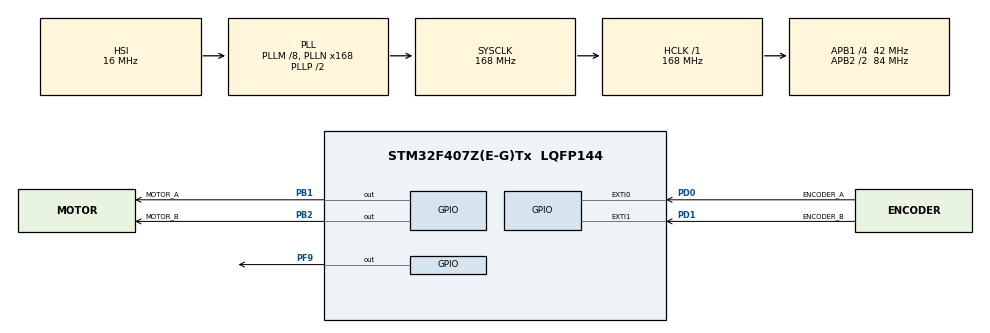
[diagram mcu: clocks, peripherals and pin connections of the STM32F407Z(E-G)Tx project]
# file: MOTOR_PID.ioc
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Mcu.Family=STM32F4
Mcu.Name=STM32F407Z(E-G)Tx
Mcu.Package=LQFP144
NVIC.EXTI0_IRQn=true\:0\:0\:false\:false\:true\:true\:true
NVIC.EXTI1_IRQn=true\:0\:0\:false\:false\:true\:true\:true
NVIC.PriorityGroup=NVIC_PRIORITYGROUP_4
NVIC.TIM2_IRQn=true\:0\:0\:false\:false\:true\:true\:true
NVIC.TIM3_IRQn=true\:0\:0\:false\:false\:true\:true\:true
PA13.Mode=Trace_Asynchronous_SW
PA13.Signal=SYS_JTMS-SWDIO
PA14.Mode=Trace_Asynchronous_SW
PA14.Signal=SYS_JTCK-SWCLK
PB1.GPIO_Label=MOTOR_A
PB1.Signal=GPIO_Output
PB2.GPIO_Label=MOTOR_B
PB2.Signal=GPIO_Output
PB3.Mode=Trace_Asynchronous_SW
PB3.Signal=SYS_JTDO-SWO
PD0.GPIO_Label=ENCODER_A
PD0.GPIO_ModeDefaultEXTI=GPIO_MODE_IT_RISING_FALLING
PD0.Signal=GPXTI0
PD1.GPIO_Label=ENCODER_B
PD1.GPIO_ModeDefaultEXTI=GPIO_MODE_IT_RISING_FALLING
PD1.Signal=GPXTI1
PF9.Signal=GPIO_Output
ProjectManager.HeapSize=0x200
ProjectManager.StackSize=0x400
ProjectManager.TargetToolchain=MDK-ARM V5.32
RCC.48MHZClocksFreq_Value=84000000
RCC.AHBFreq_Value=168000000
RCC.APB1CLKDivider=RCC_HCLK_DIV4
RCC.APB1Freq_Value=42000000
RCC.APB1TimFreq_Value=84000000
RCC.APB2CLKDivider=RCC_HCLK_DIV2
RCC.APB2Freq_Value=84000000
RCC.APB2TimFreq_Value=168000000
RCC.CortexFreq_Value=168000000
RCC.HCLKFreq_Value=168000000
RCC.HSE_VALUE=25000000
RCC.HSI_VALUE=16000000
RCC.LSE_VALUE=32768
RCC.PLLM=8
RCC.PLLN=168
RCC.SYSCLKFreq_VALUE=168000000
RCC.SYSCLKSource=RCC_SYSCLKSOURCE_PLLCLK
RCC.VCOOutputFreq_Value=336000000
TIM2.AutoReloadPreload=TIM_AUTORELOAD_PRELOAD_ENABLE
TIM2.Period=99
TIM2.Prescaler=167
TIM3.AutoReloadPreload=TIM_AUTORELOAD_PRELOAD_ENABLE
TIM3.Period=99
TIM3.Prescaler=1679
VP_TIM2_VS_ClockSourceINT.Mode=Internal
VP_TIM3_VS_ClockSourceINT.Mode=Internal
board=custom

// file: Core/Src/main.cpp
/* USER CODE BEGIN Header */
/**
  ******************************************************************************
  * @file           : main.c
  * @brief          : Main program body
  ******************************************************************************
  * @attention
  *
  * Copyright (c) 2022 STMicroelectronics.
  * All rights reserved.
  *
  * This software is licensed under terms that can be found in the LICENSE file
  * in the root directory of this software component.
  * If no LICENSE file comes with this software, it is provided AS-IS.
  *
  ******************************************************************************
  */
/* USER CODE END Header */
#include "main.h"

/* USER CODE BEGIN Includes */
#include "PWM.hpp"
#include "motor.hpp"
#include <stdio.h>
/* USER CODE END Includes */

/* USER CODE BEGIN PTD */
extern MOTOR motor;
/* USER CODE END PTD */

TIM_HandleTypeDef htim2;
TIM_HandleTypeDef htim3;

void SystemClock_Config(void);
static void MX_GPIO_Init(void);
static void MX_TIM2_Init(void);
static void MX_TIM3_Init(void);

int main(void)
{
  /* USER CODE BEGIN 1 */
  int temp;
  /* USER CODE END 1 */

  /* MCU Configuration--------------------------------------------------------*/

  /* Reset of all peripherals, Initializes the Flash interface and the Systick. */
  HAL_Init();

  /* Configure the system clock */
  SystemClock_Config();

  /* Initialize all configured peripherals */
  MX_GPIO_Init();
  MX_TIM2_Init();
  MX_TIM3_Init();
  /* USER CODE BEGIN 2 */
  PWM_Init();
  HAL_TIM_Base_Start_IT(&htim2);
  HAL_TIM_Base_Start_IT(&htim3);
  /* USER CODE END 2 */

  /* Infinite loop */
  /* USER CODE BEGIN WHILE */
  while (1)
  {
    //motor.SetVoltage(100);
    motor.SetPosition(temp -= 64*30);
    HAL_Delay(5000);
    //motor.SetVoltage(-100);
    //HAL_Delay(3000);
    printf("err=%d\n", motor.Position() - temp);
    HAL_Delay(5000);
    HAL_GPIO_TogglePin(GPIOF, GPIO_PIN_9);
    /* USER CODE END WHILE */

  }
}

void SystemClock_Config(void)
{
  RCC_OscInitTypeDef RCC_OscInitStruct = {0};
  RCC_ClkInitTypeDef RCC_ClkInitStruct = {0};

  /** Configure the main internal regulator output voltage
  */
  __HAL_RCC_PWR_CLK_ENABLE();
  __HAL_PWR_VOLTAGESCALING_CONFIG(PWR_REGULATOR_VOLTAGE_SCALE1);
  /** Initializes the RCC Oscillators according to the specified parameters
  * in the RCC_OscInitTypeDef structure.
  */
  RCC_OscInitStruct.OscillatorType = RCC_OSCILLATORTYPE_HSI;
  RCC_OscInitStruct.HSIState = RCC_HSI_ON;
  RCC_OscInitStruct.HSICalibrationValue = RCC_HSICALIBRATION_DEFAULT;
  RCC_OscInitStruct.PLL.PLLState = RCC_PLL_ON;
  RCC_OscInitStruct.PLL.PLLSource = RCC_PLLSOURCE_HSI;
  RCC_OscInitStruct.PLL.PLLM = 8;
  RCC_OscInitStruct.PLL.PLLN = 168;
  RCC_OscInitStruct.PLL.PLLP = RCC_PLLP_DIV2;
  RCC_OscInitStruct.PLL.PLLQ = 4;
  if (HAL_RCC_OscConfig(&RCC_OscInitStruct) != HAL_OK)
  {
    Error_Handler();
  }
  /** Initializes the CPU, AHB and APB buses clocks
  */
  RCC_ClkInitStruct.ClockType = RCC_CLOCKTYPE_HCLK | RCC_CLOCKTYPE_SYSCLK | RCC_CLOCKTYPE_PCLK1 | RCC_CLOCKTYPE_PCLK2;
  RCC_ClkInitStruct.SYSCLKSource = RCC_SYSCLKSOURCE_PLLCLK;
  RCC_ClkInitStruct.AHBCLKDivider = RCC_SYSCLK_DIV1;
  RCC_ClkInitStruct.APB1CLKDivider = RCC_HCLK_DIV4;
  RCC_ClkInitStruct.APB2CLKDivider = RCC_HCLK_DIV2;

  if (HAL_RCC_ClockConfig(&RCC_ClkInitStruct, FLASH_LATENCY_5) != HAL_OK)
  {
    Error_Handler();
  }
}

static void MX_TIM2_Init(void)
{

  TIM_ClockConfigTypeDef sClockSourceConfig = {0};
  TIM_MasterConfigTypeDef sMasterConfig = {0};

  htim2.Instance = TIM2;
  htim2.Init.Prescaler = 167;
  htim2.Init.CounterMode = TIM_COUNTERMODE_UP;
  htim2.Init.Period = 99;
  htim2.Init.ClockDivision = TIM_CLOCKDIVISION_DIV1;
  htim2.Init.AutoReloadPreload = TIM_AUTORELOAD_PRELOAD_ENABLE;
  if (HAL_TIM_Base_Init(&htim2) != HAL_OK)
  {
    Error_Handler();
  }
  sClockSourceConfig.ClockSource = TIM_CLOCKSOURCE_INTERNAL;
  if (HAL_TIM_ConfigClockSource(&htim2, &sClockSourceConfig) != HAL_OK)
  {
    Error_Handler();
  }
  sMasterConfig.MasterOutputTrigger = TIM_TRGO_RESET;
  sMasterConfig.MasterSlaveMode = TIM_MASTERSLAVEMODE_DISABLE;
  if (HAL_TIMEx_MasterConfigSynchronization(&htim2, &sMasterConfig) != HAL_OK)
  {
    Error_Handler();
  }
}

static void MX_TIM3_Init(void)
{

  TIM_ClockConfigTypeDef sClockSourceConfig = {0};
  TIM_MasterConfigTypeDef sMasterConfig = {0};

  htim3.Instance = TIM3;
  htim3.Init.Prescaler = 1679;
  htim3.Init.CounterMode = TIM_COUNTERMODE_UP;
  htim3.Init.Period = 99;
  htim3.Init.ClockDivision = TIM_CLOCKDIVISION_DIV1;
  htim3.Init.AutoReloadPreload = TIM_AUTORELOAD_PRELOAD_ENABLE;
  if (HAL_TIM_Base_Init(&htim3) != HAL_OK)
  {
    Error_Handler();
  }
  sClockSourceConfig.ClockSource = TIM_CLOCKSOURCE_INTERNAL;
  if (HAL_TIM_ConfigClockSource(&htim3, &sClockSourceConfig) != HAL_OK)
  {
    Error_Handler();
  }
  sMasterConfig.MasterOutputTrigger = TIM_TRGO_RESET;
  sMasterConfig.MasterSlaveMode = TIM_MASTERSLAVEMODE_DISABLE;
  if (HAL_TIMEx_MasterConfigSynchronization(&htim3, &sMasterConfig) != HAL_OK)
  {
    Error_Handler();
  }
}

static void MX_GPIO_Init(void)
{
  GPIO_InitTypeDef GPIO_InitStruct = {0};

  /* GPIO Ports Clock Enable */
  __HAL_RCC_GPIOF_CLK_ENABLE();
  __HAL_RCC_GPIOB_CLK_ENABLE();
  __HAL_RCC_GPIOA_CLK_ENABLE();
  __HAL_RCC_GPIOD_CLK_ENABLE();

  /*Configure GPIO pin Output Level */
  HAL_GPIO_WritePin(GPIOF, GPIO_PIN_9, GPIO_PIN_RESET);

  /*Configure GPIO pin Output Level */
  HAL_GPIO_WritePin(GPIOB, MOTOR_A_Pin | MOTOR_B_Pin, GPIO_PIN_RESET);

  /*Configure GPIO pin : PF9 */
  GPIO_InitStruct.Pin = GPIO_PIN_9;
  GPIO_InitStruct.Mode = GPIO_MODE_OUTPUT_PP;
  GPIO_InitStruct.Pull = GPIO_NOPULL;
  GPIO_InitStruct.Speed = GPIO_SPEED_FREQ_LOW;
  HAL_GPIO_Init(GPIOF, &GPIO_InitStruct);

  /*Configure GPIO pins : MOTOR_A_Pin MOTOR_B_Pin */
  GPIO_InitStruct.Pin = MOTOR_A_Pin | MOTOR_B_Pin;
  GPIO_InitStruct.Mode = GPIO_MODE_OUTPUT_PP;
  GPIO_InitStruct.Pull = GPIO_NOPULL;
  GPIO_InitStruct.Speed = GPIO_SPEED_FREQ_LOW;
  HAL_GPIO_Init(GPIOB, &GPIO_InitStruct);

  /*Configure GPIO pins : ENCODER_A_Pin ENCODER_B_Pin */
  GPIO_InitStruct.Pin = ENCODER_A_Pin | ENCODER_B_Pin;
  GPIO_InitStruct.Mode = GPIO_MODE_IT_RISING_FALLING;
  GPIO_InitStruct.Pull = GPIO_NOPULL;
  HAL_GPIO_Init(GPIOD, &GPIO_InitStruct);

  /* EXTI interrupt init*/
  HAL_NVIC_SetPriority(EXTI0_IRQn, 0, 0);
  HAL_NVIC_EnableIRQ(EXTI0_IRQn);

  HAL_NVIC_SetPriority(EXTI1_IRQn, 0, 0);
  HAL_NVIC_EnableIRQ(EXTI1_IRQn);
}

void Error_Handler(void)
{
  __disable_irq();
  while (1)
  {
  }
}
